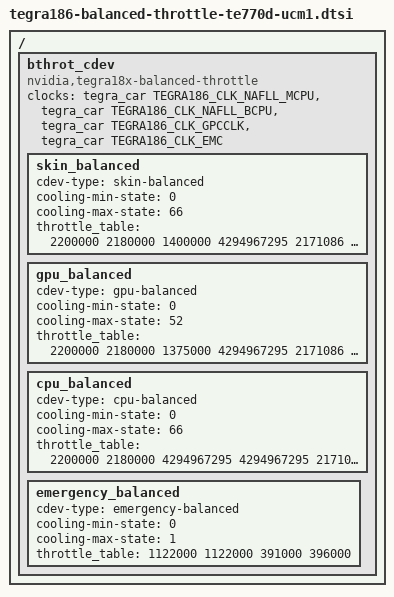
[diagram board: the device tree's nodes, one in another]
/*
 * arch/arm64/boot/dts/tegra186-platforms/tegra186-balanced-throttle-te770d-ucm1.dtsi
 *
 * Copyright (c) 2015-2016, NVIDIA CORPORATION.  All rights reserved.
 *
 * This program is free software; you can redistribute it and/or modify
 * it under the terms of the GNU General Public License as published by
 * the Free Software Foundation; version 2 of the License.
 *
 * This program is distributed in the hope that it will be useful, but WITHOUT
 * ANY WARRANTY; without even the implied warranty of MERCHANTABILITY or
 * FITNESS FOR A PARTICULAR PURPOSE.  See the GNU General Public License for
 * more details.
 *
 * You should have received a copy of the GNU General Public License along
 * with this program; if not, write to the Free Software Foundation, Inc.,
 * 51 Franklin Street, Fifth Floor, Boston, MA  02110-1301, USA.
 *
 */

/{
	bthrot_cdev {
		compatible = "nvidia,tegra18x-balanced-throttle";
		clocks = <&tegra_car TEGRA186_CLK_NAFLL_MCPU>,
				 <&tegra_car TEGRA186_CLK_NAFLL_BCPU>,
				 <&tegra_car TEGRA186_CLK_GPCCLK>,
				 <&tegra_car TEGRA186_CLK_EMC>;
		clock-names = "mcpu", "bcpu", "gpu", "emc";

		skin_balanced {
			cdev-type = "skin-balanced";
			cooling-min-state = <0>;
			cooling-max-state = <66>;
			#cooling-cells = <2>;
			throttle_table = <
				2200000	2180000	1400000	4294967295
				2171086	2151394	1381762	4294967295
				2142172	2122788	1363523	4294967295
				2113258	2094182	1345285	4294967295
				2084345	2065575	1327046	4294967295
				2055431	2036969	1308808	4294967295
				2026517	2008363	1290569	4294967295
				1997603	1979757	1272331	4294967295
				1968689	1951151	1254092	4294967295
				1939775	1922545	1235854	4294967295
				1910862	1893938	1217615	4294967295
				1881948	1865332	1199377	4294967295
				1853034	1836726	1181138	4294967295
				1824120	1808120	1162900	4294967295
				1795206	1779514	1144662	4294967295
				1766292	1750908	1126423	4294967295
				1737378	1722302	1108185	4294967295
				1708465	1693695	1089946	4294967295
				1679551	1665089	1071708	4294967295
				1650637	1636483	1053469	4294967295
				1621723	1607877	1035231	4294967295
				1592809	1579271	1016992	4294967295
				1563895	1550665	998754	4294967295
				1534982	1522058	980515	4294967295
				1506068	1493452	962277	4294967295
				1477154	1464846	944038	4294967295
				1448240	1436240	925800	4294967295
				1419326	1407634	907562	4294967295
				1390412	1379028	889323	4294967295
				1361498	1350422	871085	4294967295
				1332585	1321815	852846	4294967295
				1303671	1293209	834608	4294967295
				1274757	1264603	816369	4294967295
				1245843	1235997	798131	4294967295
				1216929	1207391	779892	4294967295
				1188015	1178785	761654	4294967295
				1159102	1150178	743415	4294967295
				1130188	1121572	725177	4294967295
				1101274	1092966	706938	4294967295
				1072360	1064360	688700	4294967295
				1043446	1035754	670462	4294967295
				1014532	1007148	652223	4294967295
				985618	978542	633985	4294967295
				956705	949935	615746	4294967295
				927791	921329	597508	4294967295
				898877	892723	579269	4294967295
				869963	864117	561031	4294967295
				841049	835511	542792	4294967295
				812135	806905	524554	4294967295
				783222	778298	506315	4294967295
				754308	749692	488077	4294967295
				725394	721086	469838	4294967295
				696480	692480	451600	4294967295
				667566	663874	433362	4294967295
				638652	635268	415123	4294967295
				609738	606662	396885	4294967295
				580825	578055	378646	4294967295
				551911	549449	360408	4294967295
				522997	520843	342169	4294967295
				494083	492237	323931	4294967295
				465169	463631	305692	4294967295
				436255	435025	287454	4294967295
				407342	406418	269215	4294967295
				378428	377812	250977	4294967295
				349514	349206	232738	4294967295
				320600	320600	214500	4294967295
			>;
		};
		gpu_balanced {
			cdev-type = "gpu-balanced";
			cooling-min-state = <0>;
			cooling-max-state = <52>;
			#cooling-cells = <2>;
			throttle_table = <
				2200000	2180000	1375000	4294967295
				2171086	2151394	1352245	4294967295
				2142172	2122788	1329490	4294967295
				2113258	2094182	1306735	4294967295
				2084345	2065575	1283980	4294967295
				2055431	2036969	1261225	4294967295
				2026517	2008363	1238471	4294967295
				1997603	1979757	1215716	4294967295
				1968689	1951151	1192961	4294967295
				1939775	1922545	1170206	4294967295
				1910862	1893938	1147451	4294967295
				1881948	1865332	1124696	4294967295
				1853034	1836726	1101941	4294967295
				1824120	1808120	1079186	4294967295
				1795206	1779514	1056431	4294967295
				1766292	1750908	1033676	4294967295
				1737378	1722302	1010922	4294967295
				1708465	1693695	988167	4294967295
				1679551	1665089	965412	4294967295
				1650637	1636483	942657	4294967295
				1621723	1607877	919902	4294967295
				1592809	1579271	897147	4294967295
				1563895	1550665	874392	4294967295
				1534982	1522058	851637	4294967295
				1506068	1493452	828882	4294967295
				1477154	1464846	806127	4294967295
				1448240	1436240	783373	4294967295
				1419326	1407634	760618	4294967295
				1390412	1379028	737863	4294967295
				1361498	1350422	715108	4294967295
				1332585	1321815	692353	4294967295
				1303671	1293209	669598	4294967295
				1274757	1264603	646843	4294967295
				1245843	1235997	624088	4294967295
				1216929	1207391	601333	4294967295
				1188015	1178785	578578	4294967295
				1159102	1150178	555824	4294967295
				1130188	1121572	533069	4294967295
				1101274	1092966	510314	4294967295
				1072360	1064360	487559	4294967295
				1043446	1035754	464804	4294967295
				1014532	1007148	442049	4294967295
				985618	978542	419294	4294967295
				956705	949935	396539	4294967295
				927791	921329	373784	4294967295
				898877	892723	351029	4294967295
				869963	864117	328275	4294967295
				841049	835511	305520	4294967295
				812135	806905	282765	4294967295
				783222	778298	260010	4294967295
				754308	749692	237255	4294967295
				725394	721086	214500	4294967295
			>;
		};
		cpu_balanced {
			cdev-type = "cpu-balanced";
			cooling-min-state = <0>;
			cooling-max-state = <66>;
			#cooling-cells = <2>;
			throttle_table = <
				2200000	2180000	4294967295	4294967295
				2171086	2151394	4294967295	4294967295
				2142172	2122788	4294967295	4294967295
				2113258	2094182	4294967295	4294967295
				2084345	2065575	4294967295	4294967295
				2055431	2036969	4294967295	4294967295
				2026517	2008363	4294967295	4294967295
				1997603	1979757	4294967295	4294967295
				1968689	1951151	4294967295	4294967295
				1939775	1922545	4294967295	4294967295
				1910862	1893938	1450000	4294967295
				1881948	1865332	1427536	4294967295
				1853034	1836726	1405073	4294967295
				1824120	1808120	1382609	4294967295
				1795206	1779514	1360145	4294967295
				1766292	1750908	1337682	4294967295
				1737378	1722302	1315218	4294967295
				1708465	1693695	1292755	4294967295
				1679551	1665089	1270291	4294967295
				1650637	1636483	1247827	4294967295
				1621723	1607877	1225364	4294967295
				1592809	1579271	1202900	4294967295
				1563895	1550665	1180436	4294967295
				1534982	1522058	1157973	4294967295
				1506068	1493452	1135509	4294967295
				1477154	1464846	1113045	4294967295
				1448240	1436240	1090582	4294967295
				1419326	1407634	1068118	4294967295
				1390412	1379028	1045655	4294967295
				1361498	1350422	1023191	4294967295
				1332585	1321815	1000727	4294967295
				1303671	1293209	978264	4294967295
				1274757	1264603	955800	4294967295
				1245843	1235997	933336	4294967295
				1216929	1207391	910873	4294967295
				1188015	1178785	888409	4294967295
				1159102	1150178	865945	4294967295
				1130188	1121572	843482	4294967295
				1101274	1092966	821018	4294967295
				1072360	1064360	798555	4294967295
				1043446	1035754	776091	4294967295
				1014532	1007148	753627	4294967295
				985618	978542	731164	4294967295
				956705	949935	708700	4294967295
				927791	921329	686236	4294967295
				898877	892723	663773	4294967295
				869963	864117	641309	4294967295
				841049	835511	618845	4294967295
				812135	806905	596382	4294967295
				783222	778298	573918	4294967295
				754308	749692	551455	4294967295
				725394	721086	528991	4294967295
				696480	692480	506527	4294967295
				667566	663874	484064	4294967295
				638652	635268	461600	4294967295
				609738	606662	439136	4294967295
				580825	578055	416673	4294967295
				551911	549449	394209	4294967295
				522997	520843	371745	4294967295
				494083	492237	349282	4294967295
				465169	463631	326818	4294967295
				436255	435025	304355	4294967295
				407342	406418	281891	4294967295
				378428	377812	259427	4294967295
				349514	349206	236964	4294967295
				320600	320600	214500	4294967295
			>;
		};
		emergency_balanced {
			cdev-type = "emergency-balanced";
			cooling-min-state = <0>;
			cooling-max-state = <1>;
			#cooling-cells = <2>;
			throttle_table = <
				1122000	1122000	391000	396000
			>;
		};
	};
};
